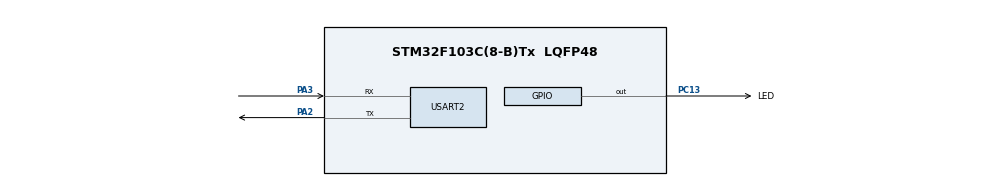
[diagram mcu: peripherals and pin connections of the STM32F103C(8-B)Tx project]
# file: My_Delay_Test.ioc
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Mcu.Family=STM32F1
Mcu.Name=STM32F103C(8-B)Tx
Mcu.Package=LQFP48
NVIC.PriorityGroup=NVIC_PRIORITYGROUP_4
PA13.Mode=Serial_Wire
PA13.Signal=SYS_JTMS-SWDIO
PA14.Mode=Serial_Wire
PA14.Signal=SYS_JTCK-SWCLK
PA2.Mode=Asynchronous
PA2.Signal=USART2_TX
PA3.Mode=Asynchronous
PA3.Signal=USART2_RX
PC13-TAMPER-RTC.GPIO_Label=LED
PC13-TAMPER-RTC.PinState=GPIO_PIN_SET
PC13-TAMPER-RTC.Signal=GPIO_Output
PD0-OSC_IN.Mode=HSE-External-Oscillator
PD0-OSC_IN.Signal=RCC_OSC_IN
PD1-OSC_OUT.Mode=HSE-External-Oscillator
PD1-OSC_OUT.Signal=RCC_OSC_OUT
ProjectManager.HeapSize=0x200
ProjectManager.StackSize=0x400
ProjectManager.TargetToolchain=MDK-ARM V5.32
RCC.AHBFreq_Value=72000000
RCC.APB1CLKDivider=RCC_HCLK_DIV2
RCC.APB1Freq_Value=36000000
RCC.APB1TimFreq_Value=72000000
RCC.APB2Freq_Value=72000000
RCC.APB2TimFreq_Value=72000000
RCC.HCLKFreq_Value=72000000
RCC.PLLMUL=RCC_PLL_MUL9
RCC.PLLSourceVirtual=RCC_PLLSOURCE_HSE
RCC.SYSCLKFreq_VALUE=72000000
RCC.SYSCLKSource=RCC_SYSCLKSOURCE_PLLCLK
RCC.USBFreq_Value=72000000
USART2.VirtualMode=VM_ASYNC
board=custom

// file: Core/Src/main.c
/* USER CODE BEGIN Header */
/**
  ******************************************************************************
  * @file           : main.c
  * @brief          : Main program body
  ******************************************************************************
  * @attention
  *
  * Copyright (c) 2025 STMicroelectronics.
  * All rights reserved.
  *
  * This software is licensed under terms that can be found in the LICENSE file
  * in the root directory of this software component.
  * If no LICENSE file comes with this software, it is provided AS-IS.
  *
  ******************************************************************************
  */
/* USER CODE END Header */
#include "main.h"
#include "usart.h"
#include "gpio.h"

void SystemClock_Config(void);

int main(void)
{

  /* MCU Configuration--------------------------------------------------------*/

  /* Reset of all peripherals, Initializes the Flash interface and the Systick. */
  LL_APB2_GRP1_EnableClock(LL_APB2_GRP1_PERIPH_AFIO);
  LL_APB1_GRP1_EnableClock(LL_APB1_GRP1_PERIPH_PWR);

  /* System interrupt init*/
  NVIC_SetPriorityGrouping(NVIC_PRIORITYGROUP_4);

  /* SysTick_IRQn interrupt configuration */
  NVIC_SetPriority(SysTick_IRQn, NVIC_EncodePriority(NVIC_GetPriorityGrouping(),15, 0));

  /** NOJTAG: JTAG-DP Disabled and SW-DP Enabled
  */
  LL_GPIO_AF_Remap_SWJ_NOJTAG();

  /* Configure the system clock */
  SystemClock_Config();

  /* USER CODE BEGIN SysInit */
   LL_delay_init(72);
  /* USER CODE END SysInit */

  /* Initialize all configured peripherals */
  MX_GPIO_Init();
  MX_USART2_UART_Init();
  /* USER CODE BEGIN 2 */
   uint32_t last_tick = LL_GetTick();  // 需确保已实现LL_GetTick()函数
  /* USER CODE END 2 */

  /* Infinite loop */
  /* USER CODE BEGIN WHILE */
  while (1)
  {

      // 检查是否到达翻转时间
        if ((LL_GetTick() - last_tick) >= 500)
        {
            // 翻转LED状态
            LL_GPIO_TogglePin(LED_GPIO_Port, LED_Pin);
            // 更新时间戳
            last_tick = LL_GetTick();
        }

    /* USER CODE END WHILE */

  }
}

void SystemClock_Config(void)
{
  LL_FLASH_SetLatency(LL_FLASH_LATENCY_2);
  while(LL_FLASH_GetLatency()!= LL_FLASH_LATENCY_2)
  {
  }
  LL_RCC_HSE_Enable();

   /* Wait till HSE is ready */
  while(LL_RCC_HSE_IsReady() != 1)
  {

  }
  LL_RCC_PLL_ConfigDomain_SYS(LL_RCC_PLLSOURCE_HSE_DIV_1, LL_RCC_PLL_MUL_9);
  LL_RCC_PLL_Enable();

   /* Wait till PLL is ready */
  while(LL_RCC_PLL_IsReady() != 1)
  {

  }
  LL_RCC_SetAHBPrescaler(LL_RCC_SYSCLK_DIV_1);
  LL_RCC_SetAPB1Prescaler(LL_RCC_APB1_DIV_2);
  LL_RCC_SetAPB2Prescaler(LL_RCC_APB2_DIV_1);
  LL_RCC_SetSysClkSource(LL_RCC_SYS_CLKSOURCE_PLL);

   /* Wait till System clock is ready */
  while(LL_RCC_GetSysClkSource() != LL_RCC_SYS_CLKSOURCE_STATUS_PLL)
  {

  }
  LL_Init1msTick(72000000);
  LL_SetSystemCoreClock(72000000);
}

void Error_Handler(void)
{
  __disable_irq();
  while (1)
  {
  }
}
